AUTOSAR XML (schema 4-2-2)
package /STELLANTIS/EPT/ASWCs
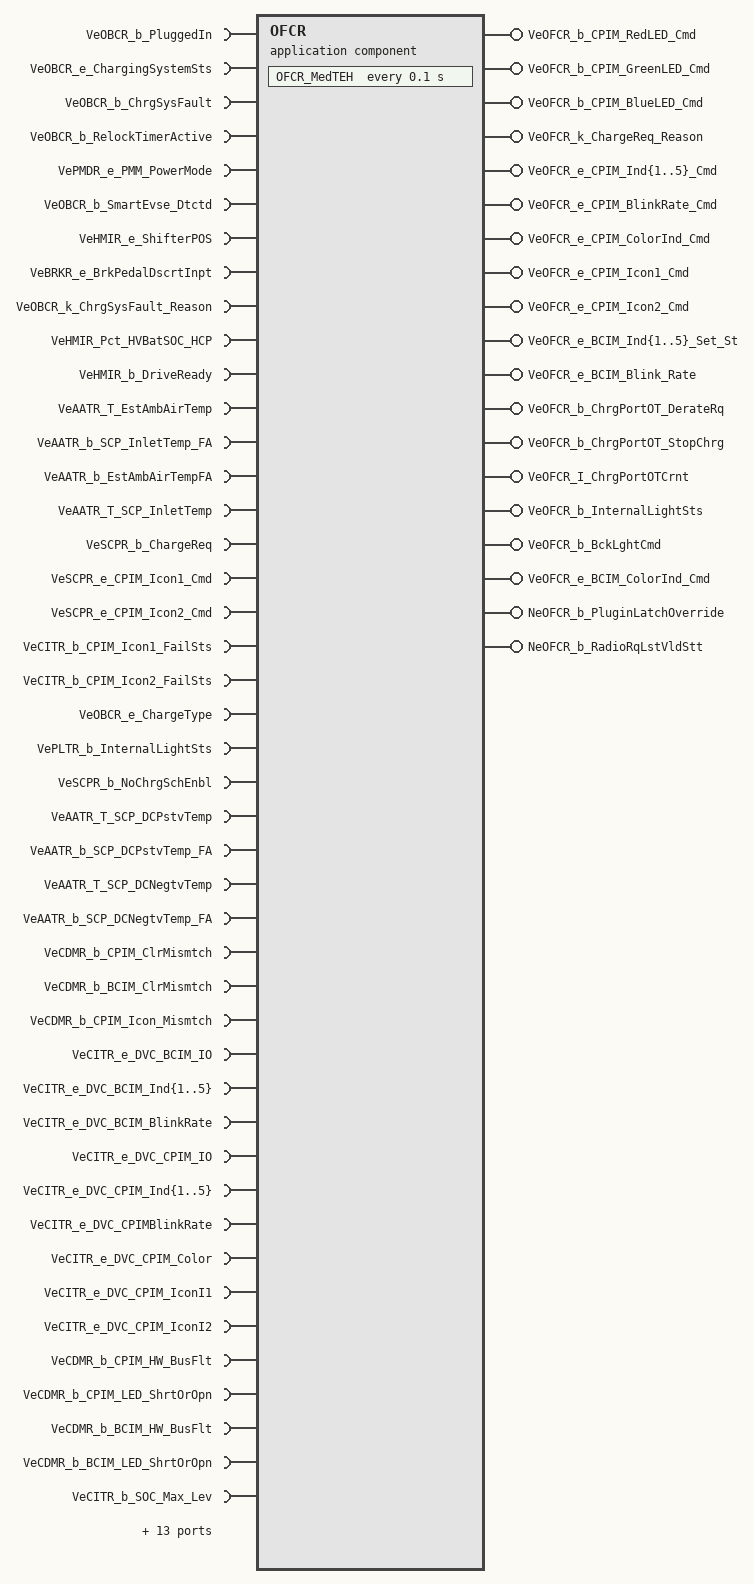
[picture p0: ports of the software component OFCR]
  application sw component type OFCR
    65 x require port:
      VeOBCR_b_PluggedIn: variation-point={short-label=vpVeOBCR_b_PluggedIn, sw-syscond=1}, nonqueued-receiver-com-spec{data-element=Value, init-value=0}, required-interface=VeOBCR_b_PluggedIn
      VeOBCR_e_ChargingSystemSts: variation-point={short-label=vpVeOBCR_e_ChargingSystemSts, sw-syscond=1}, nonqueued-receiver-com-spec{data-element=Value, init-value=CeOBCR_e_NotCharging}, required-interface=VeOBCR_e_ChargingSystemSts
      VeOBCR_b_ChrgSysFault: variation-point={short-label=vpVeOBCR_b_ChrgSysFault, sw-syscond=1}, nonqueued-receiver-com-spec{data-element=Value, init-value=0}, required-interface=VeOBCR_b_ChrgSysFault
      VeOBCR_b_RelockTimerActive: variation-point={short-label=vpVeOBCR_b_RelockTimerActive, sw-syscond=1}, nonqueued-receiver-com-spec{data-element=Value, init-value=0}, required-interface=VeOBCR_b_RelockTimerActive
      VePMDR_e_PMM_PowerMode: variation-point={short-label=vpVePMDR_e_PMM_PowerMode, sw-syscond=1}, nonqueued-receiver-com-spec{data-element=Value, init-value=CePMDR_e_PowerMode_Off}, required-interface=VePMDR_e_PMM_PowerMode
      VeOBCR_b_SmartEvse_Dtctd: variation-point={short-label=vpVeOBCR_b_SmartEvse_Dtctd, sw-syscond=1}, nonqueued-receiver-com-spec{data-element=Value, init-value=0}, required-interface=VeOBCR_b_SmartEvse_Dtctd
      VeHMIR_e_ShifterPOS: variation-point={short-label=vpVeHMIR_e_ShifterPOS, sw-syscond=1}, nonqueued-receiver-com-spec{data-element=Value, init-value=CeHMIR_e_ShifterPosNoSelection}, required-interface=VeHMIR_e_ShifterPOS
      VeBRKR_e_BrkPedalDscrtInpt: variation-point={short-label=vpVeBRKR_e_BrkPedalDscrtInpt, sw-syscond=1}, nonqueued-receiver-com-spec{data-element=Value, init-value=CeBRKR_e_BrkNotApplied}, required-interface=VeBRKR_e_BrkPedalDscrtInpt
      VeOBCR_k_ChrgSysFault_Reason: variation-point={short-label=vpVeOBCR_k_ChrgSysFault_Reason, sw-syscond=1}, nonqueued-receiver-com-spec{data-element=Value, init-value=0}, required-interface=VeOBCR_k_ChrgSysFault_Reason
      VeHMIR_Pct_HVBatSOC_HCP: variation-point={short-label=vpVeHMIR_Pct_HVBatSOC_HCP, sw-syscond=1}, nonqueued-receiver-com-spec{data-element=Value, init-value=0}, required-interface=VeHMIR_Pct_HVBatSOC_HCP
      VeHMIR_b_DriveReady: variation-point={short-label=vpVeHMIR_b_DriveReady, sw-syscond=1}, nonqueued-receiver-com-spec{data-element=Value, init-value=0}, required-interface=VeHMIR_b_DriveReady
      VeAATR_T_EstAmbAirTemp: variation-point={short-label=vpVeAATR_T_EstAmbAirTemp, sw-syscond=1}, nonqueued-receiver-com-spec{data-element=Value, init-value=0}, required-interface=VeAATR_T_EstAmbAirTemp
      VeAATR_b_SCP_InletTemp_FA: variation-point={short-label=vpVeAATR_b_SCP_InletTemp_FA, sw-syscond=1}, nonqueued-receiver-com-spec{data-element=Value, init-value=0}, required-interface=VeAATR_b_SCP_InletTemp_FA
      VeAATR_b_EstAmbAirTempFA: variation-point={short-label=vpVeAATR_b_EstAmbAirTempFA, sw-syscond=1}, nonqueued-receiver-com-spec{data-element=Value, init-value=0}, required-interface=VeAATR_b_EstAmbAirTempFA
      VeAATR_T_SCP_InletTemp: variation-point={short-label=vpVeAATR_T_SCP_InletTemp, sw-syscond=1}, nonqueued-receiver-com-spec{data-element=Value, init-value=0}, required-interface=VeAATR_T_SCP_InletTemp
      VeSCPR_b_ChargeReq: variation-point={short-label=vpVeSCPR_b_ChargeReq, sw-syscond=1}, nonqueued-receiver-com-spec{data-element=Value, init-value=0}, required-interface=VeSCPR_b_ChargeReq
      VeSCPR_e_CPIM_Icon1_Cmd: variation-point={short-label=vpVeSCPR_e_CPIM_Icon1_Cmd, sw-syscond=1}, nonqueued-receiver-com-spec{data-element=Value, init-value=CeCITR_e_CPIM_Icon_OFF}, required-interface=VeSCPR_e_CPIM_Icon1_Cmd
      VeSCPR_e_CPIM_Icon2_Cmd: variation-point={short-label=vpVeSCPR_e_CPIM_Icon2_Cmd, sw-syscond=1}, nonqueued-receiver-com-spec{data-element=Value, init-value=CeCITR_e_CPIM_Icon_OFF}, required-interface=VeSCPR_e_CPIM_Icon2_Cmd
      VeCITR_b_CPIM_Icon1_FailSts: variation-point={short-label=vpVeCITR_b_CPIM_Icon1_FailSts, sw-syscond=1}, nonqueued-receiver-com-spec{data-element=Value, init-value=0}, required-interface=VeCITR_b_CPIM_Icon1_FailSts
      VeCITR_b_CPIM_Icon2_FailSts: variation-point={short-label=vpVeCITR_b_CPIM_Icon2_FailSts, sw-syscond=1}, nonqueued-receiver-com-spec{data-element=Value, init-value=0}, required-interface=VeCITR_b_CPIM_Icon2_FailSts
      VeOBCR_e_ChargeType: variation-point={short-label=vpVeOBCR_e_ChargeType, sw-syscond=1}, nonqueued-receiver-com-spec{data-element=Value, init-value=CeOBCR_e_AC}, required-interface=VeOBCR_e_ChargeType
      VePLTR_b_InternalLightSts: variation-point={short-label=vpVePLTR_b_InternalLightSts, sw-syscond=1}, nonqueued-receiver-com-spec{data-element=Value, init-value=0}, required-interface=VePLTR_b_InternalLightSts
      VeSCPR_b_NoChrgSchEnbl: variation-point={short-label=vpVeSCPR_b_NoChrgSchEnbl, sw-syscond=1}, nonqueued-receiver-com-spec{data-element=Value, init-value=0}, required-interface=VeSCPR_b_NoChrgSchEnbl
      VeAATR_T_SCP_DCPstvTemp: variation-point={short-label=vpVeAATR_T_SCP_DCPstvTemp, sw-syscond=1}, nonqueued-receiver-com-spec{data-element=Value, init-value=0}, required-interface=VeAATR_T_SCP_DCPstvTemp
      VeAATR_b_SCP_DCPstvTemp_FA: variation-point={short-label=vpVeAATR_b_SCP_DCPstvTemp_FA, sw-syscond=1}, nonqueued-receiver-com-spec{data-element=Value, init-value=0}, required-interface=VeAATR_b_SCP_DCPstvTemp_FA
      VeAATR_T_SCP_DCNegtvTemp: variation-point={short-label=vpVeAATR_T_SCP_DCNegtvTemp, sw-syscond=1}, nonqueued-receiver-com-spec{data-element=Value, init-value=0}, required-interface=VeAATR_T_SCP_DCNegtvTemp
      VeAATR_b_SCP_DCNegtvTemp_FA: variation-point={short-label=vpVeAATR_b_SCP_DCNegtvTemp_FA, sw-syscond=1}, nonqueued-receiver-com-spec{data-element=Value, init-value=0}, required-interface=VeAATR_b_SCP_DCNegtvTemp_FA
      VeCDMR_b_CPIM_ClrMismtch: variation-point={short-label=vpVeCDMR_b_CPIM_ClrMismtch, sw-syscond=1}, nonqueued-receiver-com-spec{data-element=Value, init-value=0}, required-interface=VeCDMR_b_CPIM_ClrMismtch
      VeCDMR_b_BCIM_ClrMismtch: variation-point={short-label=vpVeCDMR_b_BCIM_ClrMismtch, sw-syscond=1}, nonqueued-receiver-com-spec{data-element=Value, init-value=0}, required-interface=VeCDMR_b_BCIM_ClrMismtch
      VeCDMR_b_CPIM_Icon_Mismtch: variation-point={short-label=vpVeCDMR_b_CPIM_Icon_Mismtch, sw-syscond=1}, nonqueued-receiver-com-spec{data-element=Value, init-value=0}, required-interface=VeCDMR_b_CPIM_Icon_Mismtch
      VeCITR_e_DVC_BCIM_IO: variation-point={short-label=vpVeCITR_e_DVC_BCIM_IO, sw-syscond=1}, nonqueued-receiver-com-spec{data-element=Value, init-value=CeODCR_e_Return_ECU_Cntrl}, required-interface=VeCITR_e_DVC_BCIM_IO
      VeCITR_e_DVC_BCIM_Ind{1..5}: variation-point={short-label=vpVeCITR_e_DVC_BCIM_Ind{1..5}, sw-syscond=1}, nonqueued-receiver-com-spec{data-element=Value, init-value=CeCITR_e_BCIM_Ind_Off}, required-interface=VeCITR_e_DVC_BCIM_Ind{1..5}
      VeCITR_e_DVC_BCIM_BlinkRate: variation-point={short-label=vpVeCITR_e_DVC_BCIM_BlinkRate, sw-syscond=1}, nonqueued-receiver-com-spec{data-element=Value, init-value=CeCITR_e_BCIM_NoBlink}, required-interface=VeCITR_e_DVC_BCIM_BlinkRate
      VeCITR_e_DVC_CPIM_IO: variation-point={short-label=vpVeCITR_e_DVC_CPIM_IO, sw-syscond=1}, nonqueued-receiver-com-spec{data-element=Value, init-value=CeODCR_e_Return_ECU_Cntrl}, required-interface=VeCITR_e_DVC_CPIM_IO
      VeCITR_e_DVC_CPIM_Ind{1..5}: variation-point={short-label=vpVeCITR_e_DVC_CPIM_Ind{1..5}, sw-syscond=1}, nonqueued-receiver-com-spec{data-element=Value, init-value=CeCITR_e_CPIM_Ind_Off}, required-interface=VeCITR_e_DVC_CPIM_Ind{1..5}
      VeCITR_e_DVC_CPIMBlinkRate: variation-point={short-label=vpVeCITR_e_DVC_CPIMBlinkRate, sw-syscond=1}, nonqueued-receiver-com-spec{data-element=Value, init-value=CeCITR_e_CPIM_NoBlink}, required-interface=VeCITR_e_DVC_CPIMBlinkRate
      VeCITR_e_DVC_CPIM_Color: variation-point={short-label=vpVeCITR_e_DVC_CPIM_Color, sw-syscond=1}, nonqueued-receiver-com-spec{data-element=Value, init-value=CeCITR_e_CPIM_NoColor}, required-interface=VeCITR_e_DVC_CPIM_Color
      VeCITR_e_DVC_CPIM_IconI1: variation-point={short-label=vpVeCITR_e_DVC_CPIM_IconI1, sw-syscond=1}, nonqueued-receiver-com-spec{data-element=Value, init-value=CeCITR_e_CPIM_Icon_OFF}, required-interface=VeCITR_e_DVC_CPIM_IconI1
      VeCITR_e_DVC_CPIM_IconI2: variation-point={short-label=vpVeCITR_e_DVC_CPIM_IconI2, sw-syscond=1}, nonqueued-receiver-com-spec{data-element=Value, init-value=CeCITR_e_CPIM_Icon_OFF}, required-interface=VeCITR_e_DVC_CPIM_IconI2
      VeCDMR_b_CPIM_HW_BusFlt: variation-point={short-label=vpVeCDMR_b_CPIM_HW_BusFlt, sw-syscond=1}, nonqueued-receiver-com-spec{data-element=Value, init-value=0}, required-interface=VeCDMR_b_CPIM_HW_BusFlt
      VeCDMR_b_CPIM_LED_ShrtOrOpn: variation-point={short-label=vpVeCDMR_b_CPIM_LED_ShrtOrOpn, sw-syscond=1}, nonqueued-receiver-com-spec{data-element=Value, init-value=0}, required-interface=VeCDMR_b_CPIM_LED_ShrtOrOpn
      VeCDMR_b_BCIM_HW_BusFlt: variation-point={short-label=vpVeCDMR_b_BCIM_HW_BusFlt, sw-syscond=1}, nonqueued-receiver-com-spec{data-element=Value, init-value=0}, required-interface=VeCDMR_b_BCIM_HW_BusFlt
      VeCDMR_b_BCIM_LED_ShrtOrOpn: variation-point={short-label=vpVeCDMR_b_BCIM_LED_ShrtOrOpn, sw-syscond=1}, nonqueued-receiver-com-spec{data-element=Value, init-value=0}, required-interface=VeCDMR_b_BCIM_LED_ShrtOrOpn
      VeCITR_b_SOC_Max_Lev: variation-point={short-label=vpVeCITR_b_SOC_Max_Lev, sw-syscond=1}, nonqueued-receiver-com-spec{data-element=Value, init-value=0}, required-interface=VeCITR_b_SOC_Max_Lev
      VeCITR_e_ChrgrFlapSts: variation-point={short-label=vpVeCITR_e_ChrgrFlapSts, sw-syscond=1}, nonqueued-receiver-com-spec{data-element=Value, init-value=CeCITR_e_ChrgrFlap_Closed}, required-interface=VeCITR_e_ChrgrFlapSts
      VeCITR_e_DVC_BCIM_Color: variation-point={short-label=vpVeCITR_e_DVC_BCIM_Color, sw-syscond=1}, nonqueued-receiver-com-spec{data-element=Value, init-value=CeCITR_e_BCIM_NoColor}, required-interface=VeCITR_e_DVC_BCIM_Color
      VeOBCR_b_SecureConnV2L: variation-point={short-label=vpVeOBCR_b_SecureConnV2L, sw-syscond=1}, nonqueued-receiver-com-spec{data-element=Value, init-value=0}, required-interface=VeOBCR_b_SecureConnV2L
      VeVTLR_e_DschrgSysSts: variation-point={short-label=vpVeVTLR_e_DschrgSysSts, sw-syscond=1}, nonqueued-receiver-com-spec{data-element=Value, init-value=CeVTLR_e_DschrgInactv}, required-interface=VeVTLR_e_DschrgSysSts
      VeVTLR_b_EnableDischarge: variation-point={short-label=vpVeVTLR_b_EnableDischarge, sw-syscond=1}, nonqueued-receiver-com-spec{data-element=Value, init-value=0}, required-interface=VeVTLR_b_EnableDischarge
      VeVTLR_b_Rdy4ShtDwn: variation-point={short-label=vpVeVTLR_b_Rdy4ShtDwn, sw-syscond=1}, nonqueued-receiver-com-spec{data-element=Value, init-value=0}, required-interface=VeVTLR_b_Rdy4ShtDwn
      VeDMAB_y_StatusByte_LIN{1..3}_BusOff: variation-point={short-label=vpVeDMAB_y_StatusByte_LIN{1..3}_BusOff, sw-syscond=1}, nonqueued-receiver-com-spec{data-element=Value, init-value=0}, required-interface=VeDMAB_y_StatusByte_LIN{1..3}_BusOff
      VeDMAB_y_StatusByte_LostCommBCIM: variation-point={short-label=vpVeDMAB_y_StatusByte_LostCommBCIM, sw-syscond=1}, nonqueued-receiver-com-spec{data-element=Value, init-value=0}, required-interface=VeDMAB_y_StatusByte_LostCommBCIM
      VeDMAB_y_StatusByte_LostCommCPIM: variation-point={short-label=vpVeDMAB_y_StatusByte_LostCommCPIM, sw-syscond=1}, nonqueued-receiver-com-spec{data-element=Value, init-value=0}, required-interface=VeDMAB_y_StatusByte_LostCommCPIM
      VeDMAB_y_StatusByte_LostCommBCM: variation-point={short-label=vpVeDMAB_y_StatusByte_LostCommBCM, sw-syscond=1}, nonqueued-receiver-com-spec{data-element=Value, init-value=0}, required-interface=VeDMAB_y_StatusByte_LostCommBCM
      VeDMAB_y_StatusByte_Module_Failure_CPIM: variation-point={short-label=vpVeDMAB_y_StatusByte_Module_Failure_CPIM, sw-syscond=1}, nonqueued-receiver-com-spec{data-element=Value, init-value=0}, required-interface=VeDMAB_y_StatusByte_Module_Failure_CPIM
    25 x provide port:
      VeOFCR_b_CPIM_RedLED_Cmd: nonqueued-sender-com-spec{data-element=Value, init-value=0}, provided-interface=VeOFCR_b_CPIM_RedLED_Cmd
      VeOFCR_b_CPIM_GreenLED_Cmd: nonqueued-sender-com-spec{data-element=Value, init-value=0}, provided-interface=VeOFCR_b_CPIM_GreenLED_Cmd
      VeOFCR_b_CPIM_BlueLED_Cmd: nonqueued-sender-com-spec{data-element=Value, init-value=0}, provided-interface=VeOFCR_b_CPIM_BlueLED_Cmd
      VeOFCR_k_ChargeReq_Reason: nonqueued-sender-com-spec{data-element=Value, init-value=0}, provided-interface=VeOFCR_k_ChargeReq_Reason
      VeOFCR_e_CPIM_Ind{1..5}_Cmd: nonqueued-sender-com-spec{data-element=Value, init-value=CeCITR_e_CPIM_Ind_Off}, provided-interface=VeOFCR_e_CPIM_Ind{1..5}_Cmd
      VeOFCR_e_CPIM_BlinkRate_Cmd: nonqueued-sender-com-spec{data-element=Value, init-value=CeCITR_e_CPIM_NoBlink}, provided-interface=VeOFCR_e_CPIM_BlinkRate_Cmd
      VeOFCR_e_CPIM_ColorInd_Cmd: nonqueued-sender-com-spec{data-element=Value, init-value=CeCITR_e_CPIM_NoColor}, provided-interface=VeOFCR_e_CPIM_ColorInd_Cmd
      VeOFCR_e_CPIM_Icon1_Cmd: nonqueued-sender-com-spec{data-element=Value, init-value=CeCITR_e_CPIM_Icon_OFF}, provided-interface=VeOFCR_e_CPIM_Icon1_Cmd
      VeOFCR_e_CPIM_Icon2_Cmd: nonqueued-sender-com-spec{data-element=Value, init-value=CeCITR_e_CPIM_Icon_OFF}, provided-interface=VeOFCR_e_CPIM_Icon2_Cmd
      VeOFCR_e_BCIM_Ind{1..5}_Set_St: nonqueued-sender-com-spec{data-element=Value, init-value=CeCITR_e_BCIM_Ind_Off}, provided-interface=VeOFCR_e_BCIM_Ind{1..5}_Set_St
      VeOFCR_e_BCIM_Blink_Rate: nonqueued-sender-com-spec{data-element=Value, init-value=CeCITR_e_BCIM_NoBlink}, provided-interface=VeOFCR_e_BCIM_Blink_Rate
      VeOFCR_b_ChrgPortOT_DerateRq: nonqueued-sender-com-spec{data-element=Value, init-value=0}, provided-interface=VeOFCR_b_ChrgPortOT_DerateRq
      VeOFCR_b_ChrgPortOT_StopChrg: nonqueued-sender-com-spec{data-element=Value, init-value=0}, provided-interface=VeOFCR_b_ChrgPortOT_StopChrg
      VeOFCR_I_ChrgPortOTCrnt: nonqueued-sender-com-spec{data-element=Value, init-value=0}, provided-interface=VeOFCR_I_ChrgPortOTCrnt
      VeOFCR_b_InternalLightSts: nonqueued-sender-com-spec{data-element=Value, init-value=0}, provided-interface=VeOFCR_b_InternalLightSts
      VeOFCR_b_BckLghtCmd: nonqueued-sender-com-spec{data-element=Value, init-value=0}, provided-interface=VeOFCR_b_BckLghtCmd
      VeOFCR_e_BCIM_ColorInd_Cmd: nonqueued-sender-com-spec{data-element=Value, init-value=CeCITR_e_BCIM_NoColor}, provided-interface=VeOFCR_e_BCIM_ColorInd_Cmd
    require port NeOFCR_b_PluginLatchOverride_Rx: variation-point={short-label=vpNeOFCR_b_PluginLatchOverride_Rx, sw-syscond=1}, nv-require-com-spec{init-value=0, variable=NeOFCR_b_PluginLatchOverride}, required-interface=NeOFCR_b_PluginLatchOverride
    require port NeOFCR_b_RadioRqLstVldStt_Rx: variation-point={short-label=vpNeOFCR_b_RadioRqLstVldStt_Rx, sw-syscond=1}, nv-require-com-spec{init-value=0, variable=NeOFCR_b_RadioRqLstVldStt}, required-interface=NeOFCR_b_RadioRqLstVldStt
    provide port NeOFCR_b_PluginLatchOverride: variation-point={short-label=vpNeOFCR_b_PluginLatchOverride, sw-syscond=1}, nv-provide-com-spec{ram-block-init-value=0, variable=NeOFCR_b_PluginLatchOverride}, provided-interface=NeOFCR_b_PluginLatchOverride
    provide port NeOFCR_b_RadioRqLstVldStt: variation-point={short-label=vpNeOFCR_b_RadioRqLstVldStt, sw-syscond=1}, nv-provide-com-spec{ram-block-init-value=0, variable=NeOFCR_b_RadioRqLstVldStt}, provided-interface=NeOFCR_b_RadioRqLstVldStt
    behavior IB_OFCR: data-type-mapping=msADTtoIDTMapping, handle-termination-and-restart=NO-SUPPORT
      timing event Event_MedTEH: start-on-event=OFCR_MedTEH, period=0.1
      init event Event_OFCR_ac_Init: start-on-event=OFCR_ac_Init
      init event Event_PwrOn: start-on-event=OFCR_PwrOn
      init event Event_PwrOff: start-on-event=OFCR_PwrOff
      4 x runnable:
        OFCR_ac_Init
          data-send-points:
            25 x access:
              OUT_VeOFCR_b_CPIM_RedLED_Cmd_Value: accessed-variable=VeOFCR_b_CPIM_RedLED_Cmd.Value
              OUT_VeOFCR_b_CPIM_GreenLED_Cmd_Value: accessed-variable=VeOFCR_b_CPIM_GreenLED_Cmd.Value
              OUT_VeOFCR_b_CPIM_BlueLED_Cmd_Value: accessed-variable=VeOFCR_b_CPIM_BlueLED_Cmd.Value
              OUT_VeOFCR_k_ChargeReq_Reason_Value: accessed-variable=VeOFCR_k_ChargeReq_Reason.Value
              OUT_VeOFCR_e_CPIM_Ind{1..5}_Cmd_Value: accessed-variable=VeOFCR_e_CPIM_Ind{1..5}_Cmd.Value
              OUT_VeOFCR_e_CPIM_BlinkRate_Cmd_Value: accessed-variable=VeOFCR_e_CPIM_BlinkRate_Cmd.Value
              OUT_VeOFCR_e_CPIM_ColorInd_Cmd_Value: accessed-variable=VeOFCR_e_CPIM_ColorInd_Cmd.Value
              OUT_VeOFCR_e_CPIM_Icon1_Cmd_Value: accessed-variable=VeOFCR_e_CPIM_Icon1_Cmd.Value
              OUT_VeOFCR_e_CPIM_Icon2_Cmd_Value: accessed-variable=VeOFCR_e_CPIM_Icon2_Cmd.Value
              OUT_VeOFCR_e_BCIM_Ind{1..5}_Set_St_Value: accessed-variable=VeOFCR_e_BCIM_Ind{1..5}_Set_St.Value
              OUT_VeOFCR_e_BCIM_Blink_Rate_Value: accessed-variable=VeOFCR_e_BCIM_Blink_Rate.Value
              OUT_VeOFCR_b_ChrgPortOT_DerateRq_Value: accessed-variable=VeOFCR_b_ChrgPortOT_DerateRq.Value
              OUT_VeOFCR_b_ChrgPortOT_StopChrg_Value: accessed-variable=VeOFCR_b_ChrgPortOT_StopChrg.Value
              OUT_VeOFCR_I_ChrgPortOTCrnt_Value: accessed-variable=VeOFCR_I_ChrgPortOTCrnt.Value
              OUT_VeOFCR_b_InternalLightSts_Value: accessed-variable=VeOFCR_b_InternalLightSts.Value
              OUT_VeOFCR_b_BckLghtCmd_Value: accessed-variable=VeOFCR_b_BckLghtCmd.Value
              OUT_VeOFCR_e_BCIM_ColorInd_Cmd_Value: accessed-variable=VeOFCR_e_BCIM_ColorInd_Cmd.Value
        OFCR_MedTEH: variation-point={short-label=vpOFCR_MedTEH, sw-syscond=1}
          data-receive-point-by-arguments:
            65 x access:
              IN_VeAATR_T_EstAmbAirTemp_Value: accessed-variable=VeAATR_T_EstAmbAirTemp.Value, variation-point={short-label=vpIN_VeAATR_T_EstAmbAirTemp_Value, sw-syscond=1}
              IN_VeAATR_T_SCP_DCNegtvTemp_Value: accessed-variable=VeAATR_T_SCP_DCNegtvTemp.Value, variation-point={short-label=vpIN_VeAATR_T_SCP_DCNegtvTemp_Value, sw-syscond=1}
              IN_VeAATR_T_SCP_DCPstvTemp_Value: accessed-variable=VeAATR_T_SCP_DCPstvTemp.Value, variation-point={short-label=vpIN_VeAATR_T_SCP_DCPstvTemp_Value, sw-syscond=1}
              IN_VeAATR_T_SCP_InletTemp_Value: accessed-variable=VeAATR_T_SCP_InletTemp.Value, variation-point={short-label=vpIN_VeAATR_T_SCP_InletTemp_Value, sw-syscond=1}
              IN_VeAATR_b_EstAmbAirTempFA_Value: accessed-variable=VeAATR_b_EstAmbAirTempFA.Value, variation-point={short-label=vpIN_VeAATR_b_EstAmbAirTempFA_Value, sw-syscond=1}
              IN_VeAATR_b_SCP_DCNegtvTemp_FA_Value: accessed-variable=VeAATR_b_SCP_DCNegtvTemp_FA.Value, variation-point={short-label=vpIN_VeAATR_b_SCP_DCNegtvTemp_FA_Value, sw-syscond=1}
              IN_VeAATR_b_SCP_DCPstvTemp_FA_Value: accessed-variable=VeAATR_b_SCP_DCPstvTemp_FA.Value, variation-point={short-label=vpIN_VeAATR_b_SCP_DCPstvTemp_FA_Value, sw-syscond=1}
              IN_VeAATR_b_SCP_InletTemp_FA_Value: accessed-variable=VeAATR_b_SCP_InletTemp_FA.Value, variation-point={short-label=vpIN_VeAATR_b_SCP_InletTemp_FA_Value, sw-syscond=1}
              IN_VeBRKR_e_BrkPedalDscrtInpt_Value: accessed-variable=VeBRKR_e_BrkPedalDscrtInpt.Value, variation-point={short-label=vpIN_VeBRKR_e_BrkPedalDscrtInpt_Value, sw-syscond=1}
              IN_VeCDMR_b_BCIM_ClrMismtch_Value: accessed-variable=VeCDMR_b_BCIM_ClrMismtch.Value, variation-point={short-label=vpIN_VeCDMR_b_BCIM_ClrMismtch_Value, sw-syscond=1}
              IN_VeCDMR_b_BCIM_HW_BusFlt_Value: accessed-variable=VeCDMR_b_BCIM_HW_BusFlt.Value, variation-point={short-label=vpIN_VeCDMR_b_BCIM_HW_BusFlt_Value, sw-syscond=1}
              IN_VeCDMR_b_BCIM_LED_ShrtOrOpn_Value: accessed-variable=VeCDMR_b_BCIM_LED_ShrtOrOpn.Value, variation-point={short-label=vpIN_VeCDMR_b_BCIM_LED_ShrtOrOpn_Value, sw-syscond=1}
              IN_VeCDMR_b_CPIM_ClrMismtch_Value: accessed-variable=VeCDMR_b_CPIM_ClrMismtch.Value, variation-point={short-label=vpIN_VeCDMR_b_CPIM_ClrMismtch_Value, sw-syscond=1}
              IN_VeCDMR_b_CPIM_HW_BusFlt_Value: accessed-variable=VeCDMR_b_CPIM_HW_BusFlt.Value, variation-point={short-label=vpIN_VeCDMR_b_CPIM_HW_BusFlt_Value, sw-syscond=1}
              IN_VeCDMR_b_CPIM_Icon_Mismtch_Value: accessed-variable=VeCDMR_b_CPIM_Icon_Mismtch.Value, variation-point={short-label=vpIN_VeCDMR_b_CPIM_Icon_Mismtch_Value, sw-syscond=1}
              IN_VeCDMR_b_CPIM_LED_ShrtOrOpn_Value: accessed-variable=VeCDMR_b_CPIM_LED_ShrtOrOpn.Value, variation-point={short-label=vpIN_VeCDMR_b_CPIM_LED_ShrtOrOpn_Value, sw-syscond=1}
              IN_VeCITR_b_CPIM_Icon1_FailSts_Value: accessed-variable=VeCITR_b_CPIM_Icon1_FailSts.Value, variation-point={short-label=vpIN_VeCITR_b_CPIM_Icon1_FailSts_Value, sw-syscond=1}
              IN_VeCITR_b_CPIM_Icon2_FailSts_Value: accessed-variable=VeCITR_b_CPIM_Icon2_FailSts.Value, variation-point={short-label=vpIN_VeCITR_b_CPIM_Icon2_FailSts_Value, sw-syscond=1}
              IN_VeCITR_b_SOC_Max_Lev_Value: accessed-variable=VeCITR_b_SOC_Max_Lev.Value, variation-point={short-label=vpIN_VeCITR_b_SOC_Max_Lev_Value, sw-syscond=1}
              IN_VeCITR_e_ChrgrFlapSts_Value: accessed-variable=VeCITR_e_ChrgrFlapSts.Value, variation-point={short-label=vpIN_VeCITR_e_ChrgrFlapSts_Value, sw-syscond=1}
              IN_VeCITR_e_DVC_BCIM_BlinkRate_Value: accessed-variable=VeCITR_e_DVC_BCIM_BlinkRate.Value, variation-point={short-label=vpIN_VeCITR_e_DVC_BCIM_BlinkRate_Value, sw-syscond=1}
              IN_VeCITR_e_DVC_BCIM_Color_Value: accessed-variable=VeCITR_e_DVC_BCIM_Color.Value, variation-point={short-label=vpIN_VeCITR_e_DVC_BCIM_Color_Value, sw-syscond=1}
              IN_VeCITR_e_DVC_BCIM_IO_Value: accessed-variable=VeCITR_e_DVC_BCIM_IO.Value, variation-point={short-label=vpIN_VeCITR_e_DVC_BCIM_IO_Value, sw-syscond=1}
              IN_VeCITR_e_DVC_BCIM_Ind{1..5}_Value: accessed-variable=VeCITR_e_DVC_BCIM_Ind{1..5}.Value, variation-point={short-label=vpIN_VeCITR_e_DVC_BCIM_Ind{1..5}_Value, sw-syscond=1}
              IN_VeCITR_e_DVC_CPIMBlinkRate_Value: accessed-variable=VeCITR_e_DVC_CPIMBlinkRate.Value, variation-point={short-label=vpIN_VeCITR_e_DVC_CPIMBlinkRate_Value, sw-syscond=1}
              IN_VeCITR_e_DVC_CPIM_Color_Value: accessed-variable=VeCITR_e_DVC_CPIM_Color.Value, variation-point={short-label=vpIN_VeCITR_e_DVC_CPIM_Color_Value, sw-syscond=1}
              IN_VeCITR_e_DVC_CPIM_IO_Value: accessed-variable=VeCITR_e_DVC_CPIM_IO.Value, variation-point={short-label=vpIN_VeCITR_e_DVC_CPIM_IO_Value, sw-syscond=1}
              IN_VeCITR_e_DVC_CPIM_IconI1_Value: accessed-variable=VeCITR_e_DVC_CPIM_IconI1.Value, variation-point={short-label=vpIN_VeCITR_e_DVC_CPIM_IconI1_Value, sw-syscond=1}
              IN_VeCITR_e_DVC_CPIM_IconI2_Value: accessed-variable=VeCITR_e_DVC_CPIM_IconI2.Value, variation-point={short-label=vpIN_VeCITR_e_DVC_CPIM_IconI2_Value, sw-syscond=1}
              IN_VeCITR_e_DVC_CPIM_Ind{1..5}_Value: accessed-variable=VeCITR_e_DVC_CPIM_Ind{1..5}.Value, variation-point={short-label=vpIN_VeCITR_e_DVC_CPIM_Ind{1..5}_Value, sw-syscond=1}
              IN_VeDMAB_y_StatusByte_LIN{1..3}_BusOff_Value: accessed-variable=VeDMAB_y_StatusByte_LIN{1..3}_BusOff.Value, variation-point={short-label=vpIN_VeDMAB_y_StatusByte_LIN{1..3}_BusOff_Value, sw-syscond=1}
              IN_VeDMAB_y_StatusByte_LostCommBCIM_Value: accessed-variable=VeDMAB_y_StatusByte_LostCommBCIM.Value, variation-point={short-label=vpIN_VeDMAB_y_StatusByte_LostCommBCIM_Value, sw-syscond=1}
              IN_VeDMAB_y_StatusByte_LostCommBCM_Value: accessed-variable=VeDMAB_y_StatusByte_LostCommBCM.Value, variation-point={short-label=vpIN_VeDMAB_y_StatusByte_LostCommBCM_Value, sw-syscond=1}
              IN_VeDMAB_y_StatusByte_LostCommCPIM_Value: accessed-variable=VeDMAB_y_StatusByte_LostCommCPIM.Value, variation-point={short-label=vpIN_VeDMAB_y_StatusByte_LostCommCPIM_Value, sw-syscond=1}
              IN_VeDMAB_y_StatusByte_Module_Failure_CPIM_Value: accessed-variable=VeDMAB_y_StatusByte_Module_Failure_CPIM.Value, variation-point={short-label=vpIN_VeDMAB_y_StatusByte_Module_Failure_CPIM_Value, sw-syscond=1}
              IN_VeHMIR_Pct_HVBatSOC_HCP_Value: accessed-variable=VeHMIR_Pct_HVBatSOC_HCP.Value, variation-point={short-label=vpIN_VeHMIR_Pct_HVBatSOC_HCP_Value, sw-syscond=1}
              IN_VeHMIR_b_DriveReady_Value: accessed-variable=VeHMIR_b_DriveReady.Value, variation-point={short-label=vpIN_VeHMIR_b_DriveReady_Value, sw-syscond=1}
              IN_VeHMIR_e_ShifterPOS_Value: accessed-variable=VeHMIR_e_ShifterPOS.Value, variation-point={short-label=vpIN_VeHMIR_e_ShifterPOS_Value, sw-syscond=1}
              IN_VeOBCR_b_ChrgSysFault_Value: accessed-variable=VeOBCR_b_ChrgSysFault.Value, variation-point={short-label=vpIN_VeOBCR_b_ChrgSysFault_Value, sw-syscond=1}
              IN_VeOBCR_b_PluggedIn_Value: accessed-variable=VeOBCR_b_PluggedIn.Value, variation-point={short-label=vpIN_VeOBCR_b_PluggedIn_Value, sw-syscond=1}
              IN_VeOBCR_b_RelockTimerActive_Value: accessed-variable=VeOBCR_b_RelockTimerActive.Value, variation-point={short-label=vpIN_VeOBCR_b_RelockTimerActive_Value, sw-syscond=1}
              IN_VeOBCR_b_SecureConnV2L_Value: accessed-variable=VeOBCR_b_SecureConnV2L.Value, variation-point={short-label=vpIN_VeOBCR_b_SecureConnV2L_Value, sw-syscond=1}
              IN_VeOBCR_b_SmartEvse_Dtctd_Value: accessed-variable=VeOBCR_b_SmartEvse_Dtctd.Value, variation-point={short-label=vpIN_VeOBCR_b_SmartEvse_Dtctd_Value, sw-syscond=1}
              IN_VeOBCR_e_ChargeType_Value: accessed-variable=VeOBCR_e_ChargeType.Value, variation-point={short-label=vpIN_VeOBCR_e_ChargeType_Value, sw-syscond=1}
              IN_VeOBCR_e_ChargingSystemSts_Value: accessed-variable=VeOBCR_e_ChargingSystemSts.Value, variation-point={short-label=vpIN_VeOBCR_e_ChargingSystemSts_Value, sw-syscond=1}
              IN_VeOBCR_k_ChrgSysFault_Reason_Value: accessed-variable=VeOBCR_k_ChrgSysFault_Reason.Value, variation-point={short-label=vpIN_VeOBCR_k_ChrgSysFault_Reason_Value, sw-syscond=1}
              IN_VePLTR_b_InternalLightSts_Value: accessed-variable=VePLTR_b_InternalLightSts.Value, variation-point={short-label=vpIN_VePLTR_b_InternalLightSts_Value, sw-syscond=1}
              IN_VePMDR_e_PMM_PowerMode_Value: accessed-variable=VePMDR_e_PMM_PowerMode.Value, variation-point={short-label=vpIN_VePMDR_e_PMM_PowerMode_Value, sw-syscond=1}
              IN_VeSCPR_b_ChargeReq_Value: accessed-variable=VeSCPR_b_ChargeReq.Value, variation-point={short-label=vpIN_VeSCPR_b_ChargeReq_Value, sw-syscond=1}
              IN_VeSCPR_b_NoChrgSchEnbl_Value: accessed-variable=VeSCPR_b_NoChrgSchEnbl.Value, variation-point={short-label=vpIN_VeSCPR_b_NoChrgSchEnbl_Value, sw-syscond=1}
              IN_VeSCPR_e_CPIM_Icon1_Cmd_Value: accessed-variable=VeSCPR_e_CPIM_Icon1_Cmd.Value, variation-point={short-label=vpIN_VeSCPR_e_CPIM_Icon1_Cmd_Value, sw-syscond=1}
              IN_VeSCPR_e_CPIM_Icon2_Cmd_Value: accessed-variable=VeSCPR_e_CPIM_Icon2_Cmd.Value, variation-point={short-label=vpIN_VeSCPR_e_CPIM_Icon2_Cmd_Value, sw-syscond=1}
              IN_VeVTLR_b_EnableDischarge_Value: accessed-variable=VeVTLR_b_EnableDischarge.Value, variation-point={short-label=vpIN_VeVTLR_b_EnableDischarge_Value, sw-syscond=1}
              IN_VeVTLR_b_Rdy4ShtDwn_Value: accessed-variable=VeVTLR_b_Rdy4ShtDwn.Value, variation-point={short-label=vpIN_VeVTLR_b_Rdy4ShtDwn_Value, sw-syscond=1}
              IN_VeVTLR_e_DschrgSysSts_Value: accessed-variable=VeVTLR_e_DschrgSysSts.Value, variation-point={short-label=vpIN_VeVTLR_e_DschrgSysSts_Value, sw-syscond=1}
          data-send-points:
            25 x access:
              OUT_VeOFCR_b_CPIM_RedLED_Cmd_Value: accessed-variable=VeOFCR_b_CPIM_RedLED_Cmd.Value
              OUT_VeOFCR_b_CPIM_GreenLED_Cmd_Value: accessed-variable=VeOFCR_b_CPIM_GreenLED_Cmd.Value
              OUT_VeOFCR_b_CPIM_BlueLED_Cmd_Value: accessed-variable=VeOFCR_b_CPIM_BlueLED_Cmd.Value
              OUT_VeOFCR_k_ChargeReq_Reason_Value: accessed-variable=VeOFCR_k_ChargeReq_Reason.Value
              OUT_VeOFCR_e_CPIM_Ind{1..5}_Cmd_Value: accessed-variable=VeOFCR_e_CPIM_Ind{1..5}_Cmd.Value
              OUT_VeOFCR_e_CPIM_BlinkRate_Cmd_Value: accessed-variable=VeOFCR_e_CPIM_BlinkRate_Cmd.Value
              OUT_VeOFCR_e_CPIM_ColorInd_Cmd_Value: accessed-variable=VeOFCR_e_CPIM_ColorInd_Cmd.Value
              OUT_VeOFCR_e_CPIM_Icon1_Cmd_Value: accessed-variable=VeOFCR_e_CPIM_Icon1_Cmd.Value
              OUT_VeOFCR_e_CPIM_Icon2_Cmd_Value: accessed-variable=VeOFCR_e_CPIM_Icon2_Cmd.Value
              OUT_VeOFCR_e_BCIM_Ind{1..5}_Set_St_Value: accessed-variable=VeOFCR_e_BCIM_Ind{1..5}_Set_St.Value
              OUT_VeOFCR_e_BCIM_Blink_Rate_Value: accessed-variable=VeOFCR_e_BCIM_Blink_Rate.Value
              OUT_VeOFCR_b_ChrgPortOT_DerateRq_Value: accessed-variable=VeOFCR_b_ChrgPortOT_DerateRq.Value
              OUT_VeOFCR_b_ChrgPortOT_StopChrg_Value: accessed-variable=VeOFCR_b_ChrgPortOT_StopChrg.Value
              OUT_VeOFCR_I_ChrgPortOTCrnt_Value: accessed-variable=VeOFCR_I_ChrgPortOTCrnt.Value
              OUT_VeOFCR_b_InternalLightSts_Value: accessed-variable=VeOFCR_b_InternalLightSts.Value
              OUT_VeOFCR_b_BckLghtCmd_Value: accessed-variable=VeOFCR_b_BckLghtCmd.Value
              OUT_VeOFCR_e_BCIM_ColorInd_Cmd_Value: accessed-variable=VeOFCR_e_BCIM_ColorInd_Cmd.Value
        OFCR_PwrOn
          data-receive-point-by-arguments:
            access IN_NeOFCR_b_PluginLatchOverride_Rx_NeOFCR_b_PluginLatchOverride: accessed-variable=NeOFCR_b_PluginLatchOverride_Rx.NeOFCR_b_PluginLatchOverride, variation-point={short-label=vpIN_NeOFCR_b_PluginLatchOverride_Rx_NeOFCR_b_PluginLatchOverride, sw-syscond=1}
            access IN_NeOFCR_b_RadioRqLstVldStt_Rx_NeOFCR_b_RadioRqLstVldStt: accessed-variable=NeOFCR_b_RadioRqLstVldStt_Rx.NeOFCR_b_RadioRqLstVldStt, variation-point={short-label=vpIN_NeOFCR_b_RadioRqLstVldStt_Rx_NeOFCR_b_RadioRqLstVldStt, sw-syscond=1}
          data-send-points:
            25 x access:
              OUT_VeOFCR_b_CPIM_RedLED_Cmd_Value: accessed-variable=VeOFCR_b_CPIM_RedLED_Cmd.Value
              OUT_VeOFCR_b_CPIM_GreenLED_Cmd_Value: accessed-variable=VeOFCR_b_CPIM_GreenLED_Cmd.Value
              OUT_VeOFCR_b_CPIM_BlueLED_Cmd_Value: accessed-variable=VeOFCR_b_CPIM_BlueLED_Cmd.Value
              OUT_VeOFCR_k_ChargeReq_Reason_Value: accessed-variable=VeOFCR_k_ChargeReq_Reason.Value
              OUT_VeOFCR_e_CPIM_Ind{1..5}_Cmd_Value: accessed-variable=VeOFCR_e_CPIM_Ind{1..5}_Cmd.Value
              OUT_VeOFCR_e_CPIM_BlinkRate_Cmd_Value: accessed-variable=VeOFCR_e_CPIM_BlinkRate_Cmd.Value
              OUT_VeOFCR_e_CPIM_ColorInd_Cmd_Value: accessed-variable=VeOFCR_e_CPIM_ColorInd_Cmd.Value
              OUT_VeOFCR_e_CPIM_Icon1_Cmd_Value: accessed-variable=VeOFCR_e_CPIM_Icon1_Cmd.Value
              OUT_VeOFCR_e_CPIM_Icon2_Cmd_Value: accessed-variable=VeOFCR_e_CPIM_Icon2_Cmd.Value
              OUT_VeOFCR_e_BCIM_Ind{1..5}_Set_St_Value: accessed-variable=VeOFCR_e_BCIM_Ind{1..5}_Set_St.Value
              OUT_VeOFCR_e_BCIM_Blink_Rate_Value: accessed-variable=VeOFCR_e_BCIM_Blink_Rate.Value
              OUT_VeOFCR_b_ChrgPortOT_DerateRq_Value: accessed-variable=VeOFCR_b_ChrgPortOT_DerateRq.Value
              OUT_VeOFCR_b_ChrgPortOT_StopChrg_Value: accessed-variable=VeOFCR_b_ChrgPortOT_StopChrg.Value
              OUT_VeOFCR_I_ChrgPortOTCrnt_Value: accessed-variable=VeOFCR_I_ChrgPortOTCrnt.Value
              OUT_VeOFCR_b_InternalLightSts_Value: accessed-variable=VeOFCR_b_InternalLightSts.Value
              OUT_VeOFCR_b_BckLghtCmd_Value: accessed-variable=VeOFCR_b_BckLghtCmd.Value
              OUT_VeOFCR_e_BCIM_ColorInd_Cmd_Value: accessed-variable=VeOFCR_e_BCIM_ColorInd_Cmd.Value
        OFCR_PwrOff: variation-point={short-label=vpOFCR_PwrOff, sw-syscond=1}
          data-send-points:
            access OUT_NeOFCR_b_PluginLatchOverride_NeOFCR_b_PluginLatchOverride: accessed-variable=NeOFCR_b_PluginLatchOverride.NeOFCR_b_PluginLatchOverride, variation-point={short-label=vpOUT_NeOFCR_b_PluginLatchOverride_NeOFCR_b_PluginLatchOverride, sw-syscond=1}
            access OUT_NeOFCR_b_RadioRqLstVldStt_NeOFCR_b_RadioRqLstVldStt: accessed-variable=NeOFCR_b_RadioRqLstVldStt.NeOFCR_b_RadioRqLstVldStt, variation-point={short-label=vpOUT_NeOFCR_b_RadioRqLstVldStt_NeOFCR_b_RadioRqLstVldStt, sw-syscond=1}
      variation point proxy Variant_OFCR_FUNC: category=CONDITION, condition-access=1
